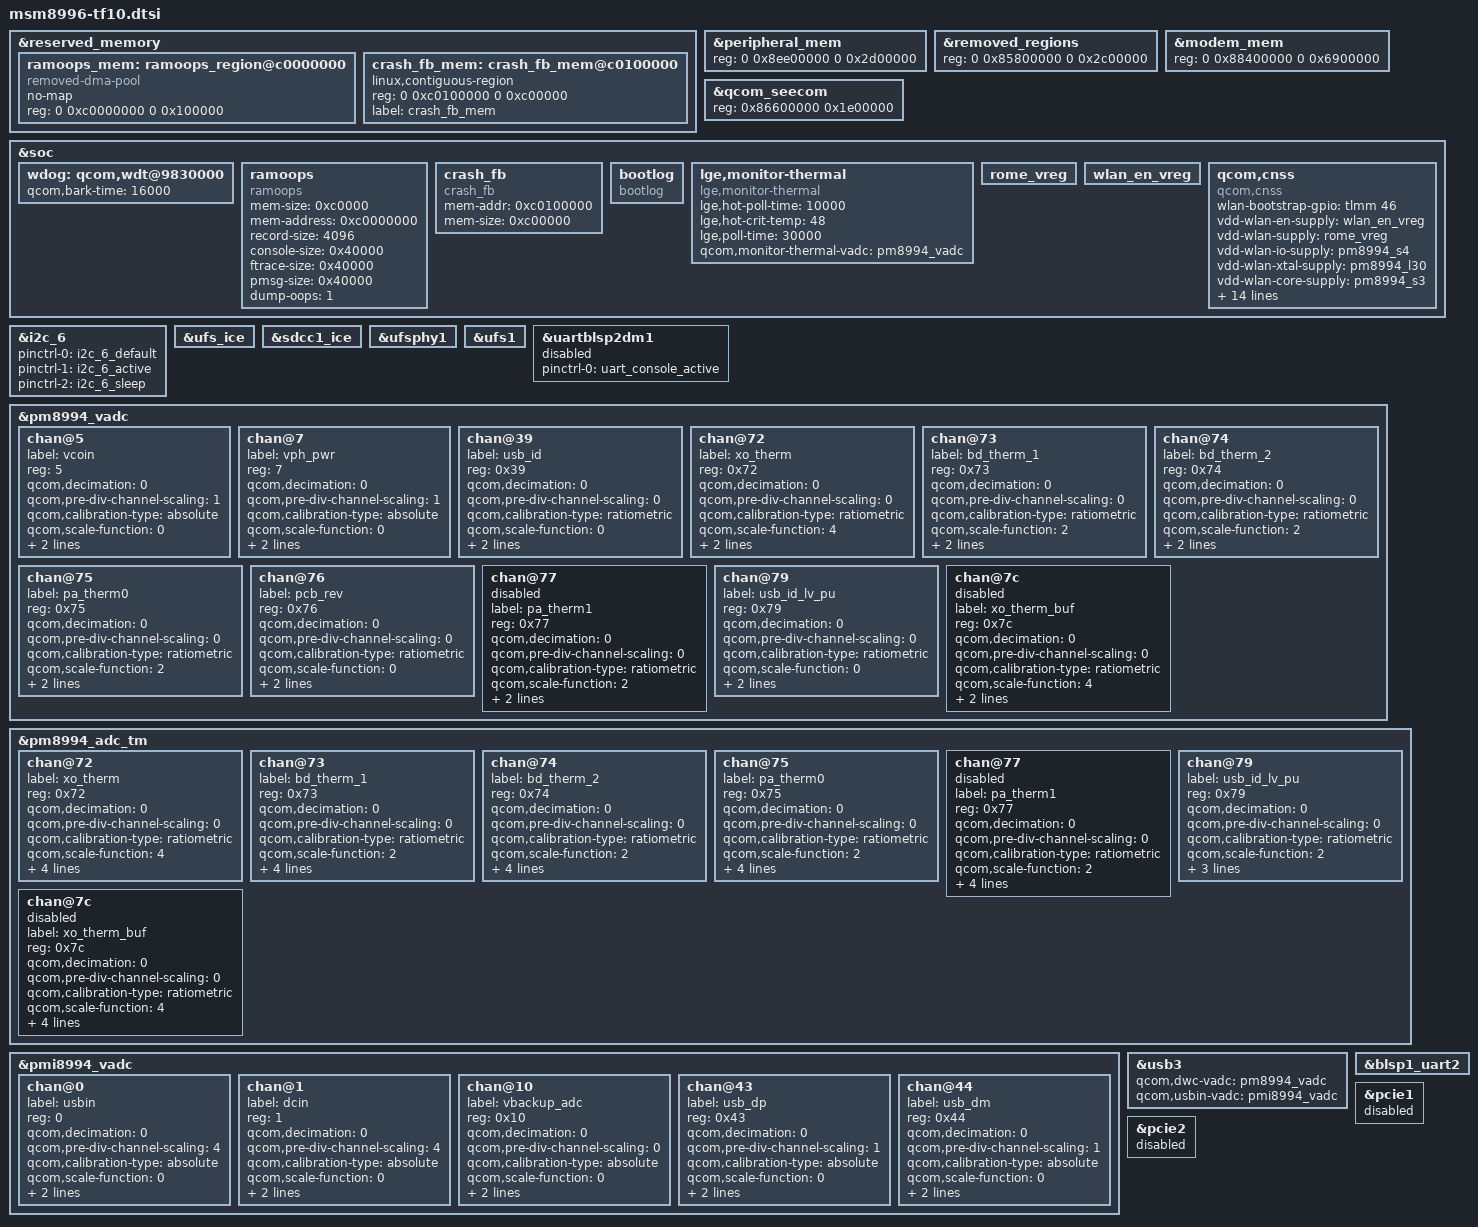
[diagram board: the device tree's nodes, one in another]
/* Copyright (c) 2015, The Linux Foundation. All rights reserved.
 *
 * This program is free software; you can redistribute it and/or modify
 * it under the terms of the GNU General Public License version 2 and
 * only version 2 as published by the Free Software Foundation.
 *
 * This program is distributed in the hope that it will be useful,
 * but WITHOUT ANY WARRANTY; without even the implied warranty of
 * MERCHANTABILITY or FITNESS FOR A PARTICULAR PURPOSE.  See the
 * GNU General Public License for more details.
 */

#include <dt-bindings/clock/msm-clocks-8996.h>
#include <dt-bindings/regulator/qcom,rpm-smd-regulator.h>
#include <dt-bindings/interrupt-controller/arm-gic.h>
#include <dt-bindings/interrupt-controller/irq.h>
#include <dt-bindings/gpio/gpio.h>
#include "msm8996-tf10-pinctrl.dtsi"
#include "msm8996-tf10-ufs.dtsi"
#include "msm8996-tf10-panel.dtsi"
#include "msm8996-tf10-pm.dtsi"
#include "msm8996-tf10-misc.dtsi"
#include "msm8996-tf10-connectivity.dtsi"
#include "msm8996-tf10-fingerprint.dtsi"
#include "msm8996-tf10-sarcontroller.dtsi"
#include "../msm8996-camera/msm8996-tf10-camera.dtsi"
#include "../tps61280.dtsi"

&reserved_memory {
	ramoops_mem: ramoops_region@c0000000 {
		compatible = "removed-dma-pool";
		no-map;
		reg = <0 0xc0000000 0 0x100000>;
	};
	crash_fb_mem: crash_fb_mem@c0100000 {
		linux,contiguous-region;
		reg = <0 0xc0100000 0 0xc00000>;
		label = "crash_fb_mem";
	};
};

&peripheral_mem {
       reg = <0 0x8ee00000 0 0x2d00000>;
};

&removed_regions {
	reg = <0 0x85800000 0 0x2c00000>;
};

&modem_mem {
	reg = <0 0x88400000 0 0x6900000>;
};

&qcom_seecom {
	reg = <0x86600000 0x1e00000>;
};

&soc {
	wdog: qcom,wdt@9830000 {
		qcom,bark-time = <16000>;
	};

	ramoops {
		compatible = "ramoops";
		mem-size = <0xc0000>;
		mem-address = <0xc0000000>;
		record-size = <4096>;
		console-size = <0x40000>;
		ftrace-size = <0x40000>;
		pmsg-size = <0x40000>;
		dump-oops = <1>;
	};

	crash_fb {
		compatible = "crash_fb";
		mem-addr = <0xc0100000>;
		mem-size = <0xc00000>;
	};

	bootlog {
		compatible = "bootlog";
	};

	lge,monitor-thermal {
		compatible = "lge,monitor-thermal";
		status = "ok";
		lge,hot-poll-time = <10000>;
		lge,hot-crit-temp = <48>;
		lge,poll-time = <30000>;
		qcom,monitor-thermal-vadc = <&pm8994_vadc>;
	};

	rome_vreg: rome_vreg {
		status = "ok";
	};

	wlan_en_vreg: wlan_en_vreg {
		status = "ok";
	};

	/* move to main soc dtb */
	///*delete QCT finger */
	///delete-node/ qcom,qbt1000;

	qcom,cnss {
		compatible = "qcom,cnss";
		wlan-bootstrap-gpio = <&tlmm 46 0>;
		vdd-wlan-en-supply = <&wlan_en_vreg>;
		vdd-wlan-supply = <&rome_vreg>;
		vdd-wlan-io-supply = <&pm8994_s4>;
		vdd-wlan-xtal-supply = <&pm8994_l30>;
		vdd-wlan-core-supply = <&pm8994_s3>;
		wlan-ant-switch-supply = <&pm8994_l18_pin_ctrl>;
		qcom,wlan-en-vreg-support;
		qcom,enable-bootstrap-gpio;
		qcom,notify-modem-status;
		pinctrl-names = "bootstrap_active", "bootstrap_sleep";
		pinctrl-0 = <&cnss_bootstrap_active>;
		pinctrl-1 = <&cnss_bootstrap_sleep>; 
		qcom,wlan-rc-num = <0>;
		qcom,wlan-ramdump-dynamic = <0x200000>;

		qcom,msm-bus,name = "msm-cnss";
		qcom,msm-bus,num-cases = <4>;
		qcom,msm-bus,num-paths = <1>;
		qcom,msm-bus,vectors-KBps =
					<45 512 0 0>,
					<45 512 41421 1520000>,
					<45 512 96650 1520000>,
					<45 512 207108 14432000>;
	};
	/* move to main soc dtb */
	///delete-node/ qcom,wil6210;
};

&i2c_6 {
       pinctrl-names = "default", "i2c_active", "i2c_sleep";
       pinctrl-0 = <&i2c_6_default>;
       pinctrl-1 = <&i2c_6_active>;
       pinctrl-2 = <&i2c_6_sleep>;
};

&ufs_ice {
	status = "ok";
};

&sdcc1_ice {
        status = "ok";
};

&ufsphy1 {
	status = "ok";
};

&ufs1 {
	status = "ok";
};

&uartblsp2dm1 {
	status = "disabled";
	pinctrl-names = "default";
	pinctrl-0 = <&uart_console_active>;
};

&pm8994_vadc {
	chan@5 {
		label = "vcoin";
		reg = <5>;
		qcom,decimation = <0>;
		qcom,pre-div-channel-scaling = <1>;
		qcom,calibration-type = "absolute";
		qcom,scale-function = <0>;
		qcom,hw-settle-time = <0>;
		qcom,fast-avg-setup = <0>;
	};

	chan@7 {
		label = "vph_pwr";
		reg = <7>;
		qcom,decimation = <0>;
		qcom,pre-div-channel-scaling = <1>;
		qcom,calibration-type = "absolute";
		qcom,scale-function = <0>;
		qcom,hw-settle-time = <0>;
		qcom,fast-avg-setup = <0>;
	};

	chan@39 {
		label = "usb_id";
		reg = <0x39>;
		qcom,decimation = <0>;
		qcom,pre-div-channel-scaling = <0>;
		qcom,calibration-type = "ratiometric";
		qcom,scale-function = <0>;
		qcom,hw-settle-time = <5>;
		qcom,fast-avg-setup = <0>;
	};

        chan@72 {
		label = "xo_therm";
		reg = <0x72>;
		qcom,decimation = <0>;
		qcom,pre-div-channel-scaling = <0>;
		qcom,calibration-type = "ratiometric";
		qcom,scale-function = <4>;
		qcom,hw-settle-time = <2>;
		qcom,fast-avg-setup = <0>;
		status = "ok";
	};

	chan@73 {
		label = "bd_therm_1";
		reg = <0x73>;
		qcom,decimation = <0>;
		qcom,pre-div-channel-scaling = <0>;
		qcom,calibration-type = "ratiometric";
		qcom,scale-function = <2>;
		qcom,hw-settle-time = <2>;
		qcom,fast-avg-setup = <0>;
		status = "ok";
	};

	chan@74 {
		label = "bd_therm_2";
		reg = <0x74>;
		qcom,decimation = <0>;
		qcom,pre-div-channel-scaling = <0>;
		qcom,calibration-type = "ratiometric";
		qcom,scale-function = <2>;
		qcom,hw-settle-time = <2>;
		qcom,fast-avg-setup = <0>;
		status = "ok";
	};

	chan@75 {
		label = "pa_therm0";
		reg = <0x75>;
		qcom,decimation = <0>;
		qcom,pre-div-channel-scaling = <0>;
		qcom,calibration-type = "ratiometric";
		qcom,scale-function = <2>;
		qcom,hw-settle-time = <2>;
		qcom,fast-avg-setup = <0>;
		status = "ok";
	};

	chan@76 {
		label = "pcb_rev";
		reg = <0x76>;
		qcom,decimation = <0>;
		qcom,pre-div-channel-scaling = <0>;
		qcom,calibration-type = "ratiometric";
		qcom,scale-function = <0>;
		qcom,hw-settle-time = <1>;
		qcom,fast-avg-setup = <0>;
	};

	chan@77 {
		label = "pa_therm1";
		reg = <0x77>;
		qcom,decimation = <0>;
		qcom,pre-div-channel-scaling = <0>;
		qcom,calibration-type = "ratiometric";
		qcom,scale-function = <2>;
		qcom,hw-settle-time = <2>;
		qcom,fast-avg-setup = <0>;
		status = "disabled";
	};

	chan@79 {
		label = "usb_id_lv_pu";
		reg = <0x79>;
		qcom,decimation = <0>;
		qcom,pre-div-channel-scaling = <0>;
		qcom,calibration-type = "ratiometric";
		qcom,scale-function = <0>;
		qcom,hw-settle-time = <5>;
		qcom,fast-avg-setup = <0>;
	};

	chan@7c {
		label = "xo_therm_buf";
		reg = <0x7c>;
		qcom,decimation = <0>;
		qcom,pre-div-channel-scaling = <0>;
		qcom,calibration-type = "ratiometric";
		qcom,scale-function = <4>;
		qcom,hw-settle-time = <2>;
		qcom,fast-avg-setup = <0>;
		status = "disabled";
	};
};

&pm8994_adc_tm {
	chan@72 {
		label = "xo_therm";
		reg = <0x72>;
		qcom,decimation = <0>;
		qcom,pre-div-channel-scaling = <0>;
		qcom,calibration-type = "ratiometric";
		qcom,scale-function = <4>;
		qcom,hw-settle-time = <2>;
		qcom,fast-avg-setup = <0>;
		qcom,btm-channel-number = <0x72>;
		qcom,thermal-node;
		status = "ok";
	};

	chan@73 {
		label = "bd_therm_1";
		reg = <0x73>;
		qcom,decimation = <0>;
		qcom,pre-div-channel-scaling = <0>;
		qcom,calibration-type = "ratiometric";
		qcom,scale-function = <2>;
		qcom,hw-settle-time = <2>;
		qcom,fast-avg-setup = <0>;
		qcom,btm-channel-number = <0x48>;
		qcom,thermal-node;
		status = "ok";
	};

	chan@74 {
		label = "bd_therm_2";
		reg = <0x74>;
		qcom,decimation = <0>;
		qcom,pre-div-channel-scaling = <0>;
		qcom,calibration-type = "ratiometric";
		qcom,scale-function = <2>;
		qcom,hw-settle-time = <2>;
		qcom,fast-avg-setup = <0>;
		qcom,btm-channel-number = <0x68>;
		qcom,thermal-node;
		status = "ok";
	};

	chan@75 {
		label = "pa_therm0";
		reg = <0x75>;
		qcom,decimation = <0>;
		qcom,pre-div-channel-scaling = <0>;
		qcom,calibration-type = "ratiometric";
		qcom,scale-function = <2>;
		qcom,hw-settle-time = <2>;
		qcom,fast-avg-setup = <0>;
		qcom,btm-channel-number = <0x70>;
		qcom,thermal-node;
		status = "ok";
	};

	chan@77 {
		label = "pa_therm1";
		reg = <0x77>;
		qcom,decimation = <0>;
		qcom,pre-div-channel-scaling = <0>;
		qcom,calibration-type = "ratiometric";
		qcom,scale-function = <2>;
		qcom,hw-settle-time = <2>;
		qcom,fast-avg-setup = <0>;
		qcom,btm-channel-number = <0x78>;
		qcom,thermal-node;
		status = "disabled";
	};

	chan@79 {
		label = "usb_id_lv_pu";
		reg = <0x79>;
		qcom,decimation = <0>;
		qcom,pre-div-channel-scaling = <0>;
		qcom,calibration-type = "ratiometric";
		qcom,scale-function = <2>;
		qcom,hw-settle-time = <2>;
		qcom,fast-avg-setup = <3>;
		qcom,btm-channel-number = <0x80>;
	};

	chan@7c {
		label = "xo_therm_buf";
		reg = <0x7c>;
		qcom,decimation = <0>;
		qcom,pre-div-channel-scaling = <0>;
		qcom,calibration-type = "ratiometric";
		qcom,scale-function = <4>;
		qcom,hw-settle-time = <2>;
		qcom,fast-avg-setup = <0>;
		qcom,btm-channel-number = <0x88>;
		qcom,thermal-node;
		status = "disabled";
	};
};

&pmi8994_vadc {
	chan@0 {
		label = "usbin";
		reg = <0>;
		qcom,decimation = <0>;
		qcom,pre-div-channel-scaling = <4>;
		qcom,calibration-type = "absolute";
		qcom,scale-function = <0>;
		qcom,hw-settle-time = <0>;
		qcom,fast-avg-setup = <0>;
	};

	chan@1 {
		label = "dcin";
		reg = <1>;
		qcom,decimation = <0>;
		qcom,pre-div-channel-scaling = <4>;
		qcom,calibration-type = "absolute";
		qcom,scale-function = <0>;
		qcom,hw-settle-time = <0>;
		qcom,fast-avg-setup = <0>;
	};

	chan@10 {
		label = "vbackup_adc";
		reg = <0x10>;
		qcom,decimation = <0>;
		qcom,pre-div-channel-scaling = <0>;
		qcom,calibration-type = "absolute";
		qcom,scale-function = <0>;
		qcom,hw-settle-time = <1>;
		qcom,fast-avg-setup = <2>;
	};

	chan@43 {
		label = "usb_dp";
		reg = <0x43>;
		qcom,decimation = <0>;
		qcom,pre-div-channel-scaling = <1>;
		qcom,calibration-type = "absolute";
		qcom,scale-function = <0>;
		qcom,hw-settle-time = <0>;
		qcom,fast-avg-setup = <0>;
	};

	chan@44 {
		label = "usb_dm";
		reg = <0x44>;
		qcom,decimation = <0>;
		qcom,pre-div-channel-scaling = <1>;
		qcom,calibration-type = "absolute";
		qcom,scale-function = <0>;
		qcom,hw-settle-time = <0>;
		qcom,fast-avg-setup = <0>;
	};
};
&usb3 {
	status = "ok";
	qcom,dwc-vadc = <&pm8994_vadc>;
	qcom,usbin-vadc = <&pmi8994_vadc>;
};

&blsp1_uart2 {
	status = "ok";
};

&pcie1 {
       status = "disabled";
};

&pcie2 {
       status = "disabled";
};

/* move to main soc dtb */
//&pil_modem {
//       /delete-property/ qcom,mx-spike-wa;
//};
